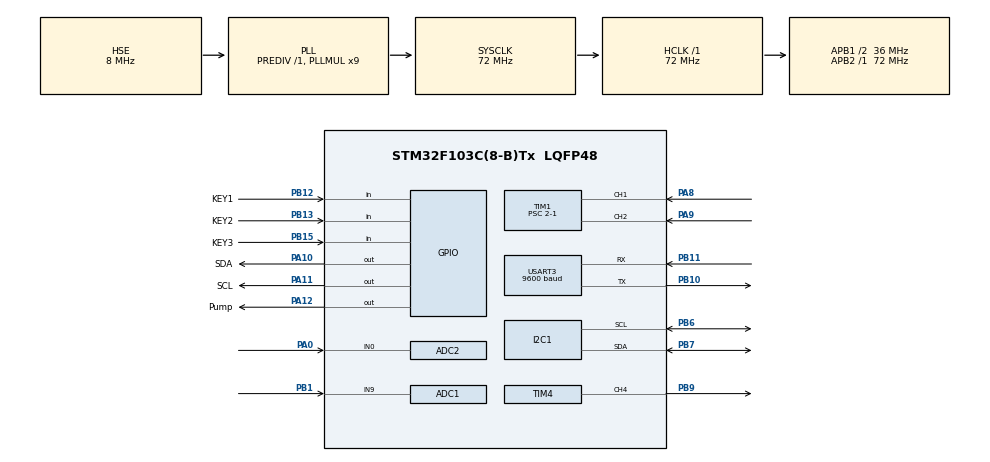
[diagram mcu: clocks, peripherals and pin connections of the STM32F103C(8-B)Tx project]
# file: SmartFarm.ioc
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ADC1.Channel-0\#ChannelRegularConversion=ADC_CHANNEL_9
ADC1.ContinuousConvMode=ENABLE
ADC1.NbrOfConversionFlag=1
ADC1.Rank-0\#ChannelRegularConversion=1
ADC1.SamplingTime-0\#ChannelRegularConversion=ADC_SAMPLETIME_239CYCLES_5
ADC1.master=1
ADC2.Channel-0\#ChannelRegularConversion=ADC_CHANNEL_0
ADC2.ContinuousConvMode=ENABLE
ADC2.NbrOfConversionFlag=1
ADC2.Rank-0\#ChannelRegularConversion=1
ADC2.SamplingTime-0\#ChannelRegularConversion=ADC_SAMPLETIME_239CYCLES_5
Dma.Request0=USART3_RX
Dma.Request1=USART3_TX
Dma.USART3_RX.0.Direction=DMA_PERIPH_TO_MEMORY
Dma.USART3_RX.0.Instance=DMA1_Channel3
Dma.USART3_RX.0.MemDataAlignment=DMA_MDATAALIGN_BYTE
Dma.USART3_RX.0.MemInc=DMA_MINC_ENABLE
Dma.USART3_RX.0.Mode=DMA_NORMAL
Dma.USART3_RX.0.PeriphDataAlignment=DMA_PDATAALIGN_BYTE
Dma.USART3_RX.0.PeriphInc=DMA_PINC_DISABLE
Dma.USART3_RX.0.Priority=DMA_PRIORITY_LOW
Dma.USART3_TX.1.Direction=DMA_MEMORY_TO_PERIPH
Dma.USART3_TX.1.Instance=DMA1_Channel2
Dma.USART3_TX.1.MemDataAlignment=DMA_MDATAALIGN_BYTE
Dma.USART3_TX.1.MemInc=DMA_MINC_ENABLE
Dma.USART3_TX.1.Mode=DMA_NORMAL
Dma.USART3_TX.1.PeriphDataAlignment=DMA_PDATAALIGN_BYTE
Dma.USART3_TX.1.PeriphInc=DMA_PINC_DISABLE
Dma.USART3_TX.1.Priority=DMA_PRIORITY_LOW
FREERTOS.Mutexes01=i2c1Mutex,Dynamic,NULL,Available
FREERTOS.Queues01=BLEQueue,16,char*,0,Dynamic,NULL,NULL
FREERTOS.Tasks01=SensorTask,24,256,StartSensorTask,As weak,NULL,Dynamic,NULL,NULL;InputTask,40,128,StartInputTask,As external,NULL,Dynamic,NULL,NULL;ScreenTask,21,128,StartScreenTask,As external,NULL,Dynamic,NULL,NULL;BLETask,8,128,StartBLETask,As external,NULL,Dynamic,NULL,NULL
FREERTOS.Timers01=BeepTimer,BeepTimerCallback,osTimerPeriodic,As external,NULL,Dynamic,NULL
FREERTOS.configTOTAL_HEAP_SIZE=10240
FREERTOS.configUSE_NEWLIB_REENTRANT=1
I2C1.I2C_Mode=I2C_Fast
Mcu.Family=STM32F1
Mcu.Name=STM32F103C(8-B)Tx
Mcu.Package=LQFP48
NVIC.DMA1_Channel2_IRQn=true\:5\:0\:false\:false\:true\:true\:false\:true\:true
NVIC.DMA1_Channel3_IRQn=true\:5\:0\:false\:false\:true\:true\:false\:true\:true
NVIC.PriorityGroup=NVIC_PRIORITYGROUP_4
NVIC.TIM3_IRQn=true\:15\:0\:false\:false\:true\:false\:false\:true\:true
NVIC.TimeBase=TIM3_IRQn
NVIC.TimeBaseIP=TIM3
NVIC.USART3_IRQn=true\:5\:0\:false\:false\:true\:true\:false\:true\:true
PA0-WKUP.Signal=ADCx_IN0
PA10.GPIO_Label=SDA
PA10.GPIO_ModeDefaultOutputPP=GPIO_MODE_OUTPUT_OD
PA10.GPIO_PuPd=GPIO_PULLUP
PA10.Signal=GPIO_Output
PA11.GPIO_Label=SCL
PA11.Signal=GPIO_Output
PA12.GPIO_Label=Pump
PA12.Signal=GPIO_Output
PA13.Mode=Serial_Wire
PA13.Signal=SYS_JTMS-SWDIO
PA14.Mode=Serial_Wire
PA14.Signal=SYS_JTCK-SWCLK
PA8.Signal=S_TIM1_CH1
PA9.Signal=S_TIM1_CH2
PB1.Signal=ADCx_IN9
PB10.Mode=Asynchronous
PB10.Signal=USART3_TX
PB11.Mode=Asynchronous
PB11.Signal=USART3_RX
PB12.GPIO_Label=KEY1
PB12.Signal=GPIO_Input
PB13.GPIO_Label=KEY2
PB13.GPIO_PuPd=GPIO_PULLUP
PB13.Signal=GPIO_Input
PB15.GPIO_Label=KEY3
PB15.GPIO_PuPd=GPIO_PULLUP
PB15.Signal=GPIO_Input
PB6.Mode=I2C
PB6.Signal=I2C1_SCL
PB7.Mode=I2C
PB7.Signal=I2C1_SDA
PB9.Signal=S_TIM4_CH4
PD0-OSC_IN.Mode=HSE-External-Oscillator
PD0-OSC_IN.Signal=RCC_OSC_IN
PD1-OSC_OUT.Mode=HSE-External-Oscillator
PD1-OSC_OUT.Signal=RCC_OSC_OUT
ProjectManager.HeapSize=0x200
ProjectManager.StackSize=0x400
ProjectManager.TargetToolchain=MDK-ARM V5.32
RCC.ADCPresc=RCC_ADCPCLK2_DIV6
RCC.AHBFreq_Value=72000000
RCC.APB1CLKDivider=RCC_HCLK_DIV2
RCC.APB1Freq_Value=36000000
RCC.APB1TimFreq_Value=72000000
RCC.APB2Freq_Value=72000000
RCC.APB2TimFreq_Value=72000000
RCC.HCLKFreq_Value=72000000
RCC.PLLMUL=RCC_PLL_MUL9
RCC.PLLSourceVirtual=RCC_PLLSOURCE_HSE
RCC.SYSCLKFreq_VALUE=72000000
RCC.SYSCLKSource=RCC_SYSCLKSOURCE_PLLCLK
RCC.USBFreq_Value=72000000
SH.ADCx_IN0.0=ADC2_IN0,IN0
SH.ADCx_IN9.0=ADC1_IN9,IN9
SH.S_TIM1_CH1.0=TIM1_CH1,Encoder_Interface
SH.S_TIM1_CH2.0=TIM1_CH2,Encoder_Interface
SH.S_TIM4_CH4.0=TIM4_CH4,PWM Generation4 CH4
TIM1.IC1Filter=15
TIM1.IC1Polarity=TIM_ICPOLARITY_FALLING
TIM1.IC2Filter=15
TIM1.Prescaler=2-1
TIM4.Channel-PWM\ Generation4\ CH4=TIM_CHANNEL_4
TIM4.Period=500-1
TIM4.Prescaler=72-1
USART3.BaudRate=9600
USART3.VirtualMode=VM_ASYNC
VP_FREERTOS_VS_CMSIS_V2.Mode=CMSIS_V2
VP_SYS_VS_tim3.Mode=TIM3
VP_TIM4_VS_ClockSourceINT.Mode=Internal
board=custom

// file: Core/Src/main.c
/* USER CODE BEGIN Header */
/**
  ******************************************************************************
  * @file           : main.c
  * @brief          : Main program body
  ******************************************************************************
  * @attention
  *
  * Copyright (c) 2026 STMicroelectronics.
  * All rights reserved.
  *
  * This software is licensed under terms that can be found in the LICENSE file
  * in the root directory of this software component.
  * If no LICENSE file comes with this software, it is provided AS-IS.
  *
  ******************************************************************************
  */
/* USER CODE END Header */
#include "main.h"
#include "cmsis_os.h"
#include "adc.h"
#include "dma.h"
#include "i2c.h"
#include "tim.h"
#include "usart.h"
#include "gpio.h"

void SystemClock_Config(void);
void MX_FREERTOS_Init(void);

int main(void)
{

  /* MCU Configuration--------------------------------------------------------*/

  /* Reset of all peripherals, Initializes the Flash interface and the Systick. */
  HAL_Init();

  /* Configure the system clock */
  SystemClock_Config();

  /* Initialize all configured peripherals */
  MX_GPIO_Init();
  MX_DMA_Init();
  MX_ADC1_Init();
  MX_ADC2_Init();
  MX_I2C1_Init();
  MX_TIM1_Init();
  MX_TIM4_Init();
  MX_USART3_UART_Init();

  /* Init scheduler */
  osKernelInitialize();  /* Call init function for freertos objects (in cmsis_os2.c) */
  MX_FREERTOS_Init();

  /* Start scheduler */
  osKernelStart();

  /* We should never get here as control is now taken by the scheduler */

  /* Infinite loop */
  while (1)
  {

  }
}

void SystemClock_Config(void)
{
  RCC_OscInitTypeDef RCC_OscInitStruct = {0};
  RCC_ClkInitTypeDef RCC_ClkInitStruct = {0};
  RCC_PeriphCLKInitTypeDef PeriphClkInit = {0};

  /** Initializes the RCC Oscillators according to the specified parameters
  * in the RCC_OscInitTypeDef structure.
  */
  RCC_OscInitStruct.OscillatorType = RCC_OSCILLATORTYPE_HSE;
  RCC_OscInitStruct.HSEState = RCC_HSE_ON;
  RCC_OscInitStruct.HSEPredivValue = RCC_HSE_PREDIV_DIV1;
  RCC_OscInitStruct.HSIState = RCC_HSI_ON;
  RCC_OscInitStruct.PLL.PLLState = RCC_PLL_ON;
  RCC_OscInitStruct.PLL.PLLSource = RCC_PLLSOURCE_HSE;
  RCC_OscInitStruct.PLL.PLLMUL = RCC_PLL_MUL9;
  if (HAL_RCC_OscConfig(&RCC_OscInitStruct) != HAL_OK)
  {
    Error_Handler();
  }

  /** Initializes the CPU, AHB and APB buses clocks
  */
  RCC_ClkInitStruct.ClockType = RCC_CLOCKTYPE_HCLK|RCC_CLOCKTYPE_SYSCLK
                              |RCC_CLOCKTYPE_PCLK1|RCC_CLOCKTYPE_PCLK2;
  RCC_ClkInitStruct.SYSCLKSource = RCC_SYSCLKSOURCE_PLLCLK;
  RCC_ClkInitStruct.AHBCLKDivider = RCC_SYSCLK_DIV1;
  RCC_ClkInitStruct.APB1CLKDivider = RCC_HCLK_DIV2;
  RCC_ClkInitStruct.APB2CLKDivider = RCC_HCLK_DIV1;

  if (HAL_RCC_ClockConfig(&RCC_ClkInitStruct, FLASH_LATENCY_2) != HAL_OK)
  {
    Error_Handler();
  }
  PeriphClkInit.PeriphClockSelection = RCC_PERIPHCLK_ADC;
  PeriphClkInit.AdcClockSelection = RCC_ADCPCLK2_DIV6;
  if (HAL_RCCEx_PeriphCLKConfig(&PeriphClkInit) != HAL_OK)
  {
    Error_Handler();
  }
}

void HAL_TIM_PeriodElapsedCallback(TIM_HandleTypeDef *htim)
{
  if (htim->Instance == TIM3)
  {
    HAL_IncTick();
  }
}

void Error_Handler(void)
{
  __disable_irq();
  while (1)
  {
  }
}

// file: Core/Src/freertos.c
/* USER CODE BEGIN Header */
/**
  ******************************************************************************
  * File Name          : freertos.c
  * Description        : Code for freertos applications
  ******************************************************************************
  * @attention
  *
  * Copyright (c) 2026 STMicroelectronics.
  * All rights reserved.
  *
  * This software is licensed under terms that can be found in the LICENSE file
  * in the root directory of this software component.
  * If no LICENSE file comes with this software, it is provided AS-IS.
  *
  ******************************************************************************
  */
/* USER CODE END Header */

#include "FreeRTOS.h"
#include "task.h"
#include "main.h"
#include "cmsis_os.h"

/* USER CODE BEGIN Includes */
#include "aht20/aht20.h"
#include "oled/oled.h"
#include "oled/font.h"
/* USER CODE END Includes */

/* Definitions for SensorTask */
osThreadId_t SensorTaskHandle;
const osThreadAttr_t SensorTask_attributes = {
  .name = "SensorTask",
  .stack_size = 256 * 4,
  .priority = (osPriority_t) osPriorityNormal,
};
/* Definitions for InputTask */
osThreadId_t InputTaskHandle;
const osThreadAttr_t InputTask_attributes = {
  .name = "InputTask",
  .stack_size = 128 * 4,
  .priority = (osPriority_t) osPriorityHigh,
};
/* Definitions for ScreenTask */
osThreadId_t ScreenTaskHandle;
const osThreadAttr_t ScreenTask_attributes = {
  .name = "ScreenTask",
  .stack_size = 128 * 4,
  .priority = (osPriority_t) osPriorityBelowNormal5,
};
/* Definitions for BLETask */
osThreadId_t BLETaskHandle;
const osThreadAttr_t BLETask_attributes = {
  .name = "BLETask",
  .stack_size = 128 * 4,
  .priority = (osPriority_t) osPriorityLow,
};
/* Definitions for BLEQueue */
osMessageQueueId_t BLEQueueHandle;
const osMessageQueueAttr_t BLEQueue_attributes = {
  .name = "BLEQueue"
};
/* Definitions for BeepTimer */
osTimerId_t BeepTimerHandle;
const osTimerAttr_t BeepTimer_attributes = {
  .name = "BeepTimer"
};
/* Definitions for i2c1Mutex */
osMutexId_t i2c1MutexHandle;
const osMutexAttr_t i2c1Mutex_attributes = {
  .name = "i2c1Mutex"
};

void StartSensorTask(void *argument);
extern void StartInputTask(void *argument);
extern void StartScreenTask(void *argument);
extern void StartBLETask(void *argument);
extern void BeepTimerCallback(void *argument);

void MX_FREERTOS_Init(void); /* (MISRA C 2004 rule 8.1) */

void MX_FREERTOS_Init(void) {
  /* Create the mutex(es) */
  /* creation of i2c1Mutex */
  i2c1MutexHandle = osMutexNew(&i2c1Mutex_attributes);

  /* Create the timer(s) */
  /* creation of BeepTimer */
  BeepTimerHandle = osTimerNew(BeepTimerCallback, osTimerPeriodic, NULL, &BeepTimer_attributes);

  /* Create the queue(s) */
  /* creation of BLEQueue */
  BLEQueueHandle = osMessageQueueNew (16, sizeof(char*), &BLEQueue_attributes);

  /* Create the thread(s) */
  /* creation of SensorTask */
  SensorTaskHandle = osThreadNew(StartSensorTask, NULL, &SensorTask_attributes);

  /* creation of InputTask */
  InputTaskHandle = osThreadNew(StartInputTask, NULL, &InputTask_attributes);

  /* creation of ScreenTask */
  ScreenTaskHandle = osThreadNew(StartScreenTask, NULL, &ScreenTask_attributes);

  /* creation of BLETask */
  BLETaskHandle = osThreadNew(StartBLETask, NULL, &BLETask_attributes);

}

__weak void StartSensorTask(void *argument)
{
  for(;;)
  {
    osDelay(1);
  }
}
